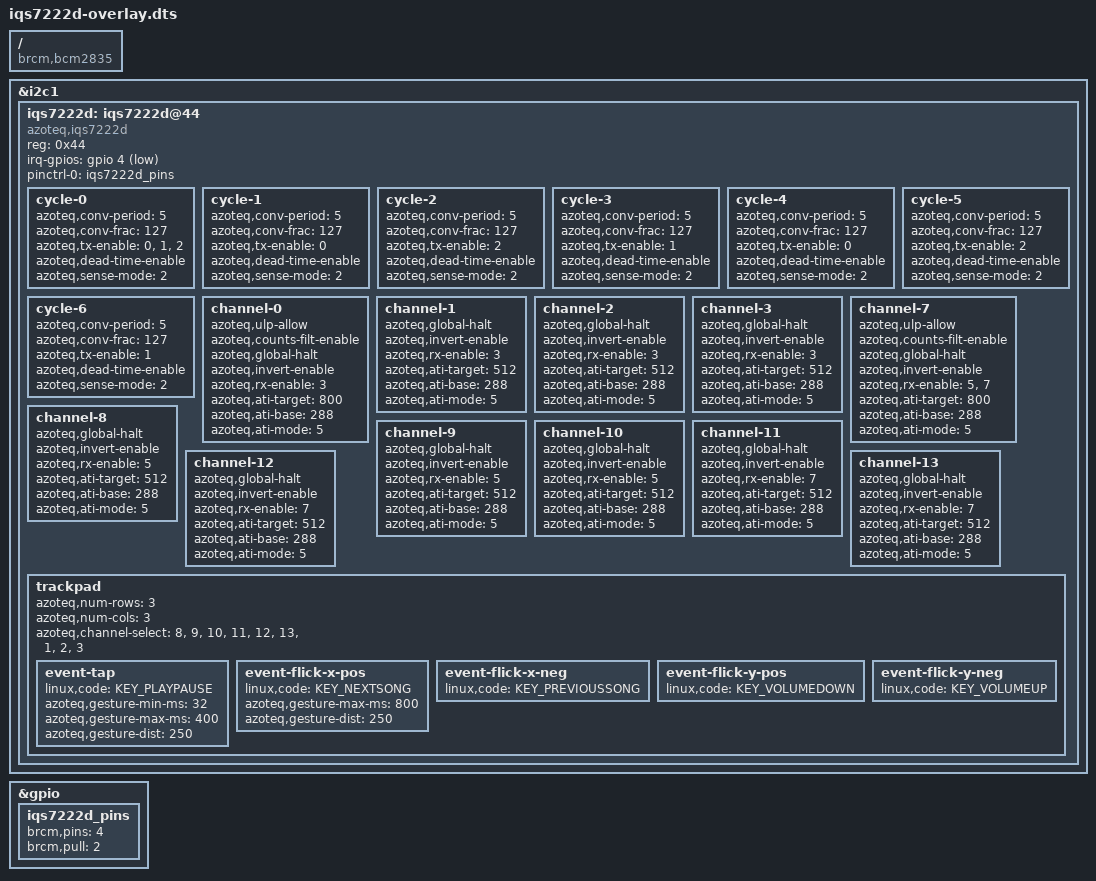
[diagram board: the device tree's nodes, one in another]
// SPDX-License-Identifier: GPL-2.0-or-later
// Definitions for Azoteq AZU045A01 + IQS7222D capacitive touch controller
/dts-v1/;
/plugin/;
#include <dt-bindings/gpio/gpio.h>
#include <dt-bindings/input/input.h>

/ {
	compatible = "brcm,bcm2835";

	fragment@0 {
		target = <&i2c1>;
		__overlay__ {
			#address-cells = <1>;
			#size-cells = <0>;
			status = "okay";

			iqs7222d: iqs7222d@44 {
				compatible = "azoteq,iqs7222d";
				reg = <0x44>;
				irq-gpios = <&gpio 4 GPIO_ACTIVE_LOW>;
				pinctrl-names = "default";
				pinctrl-0 = <&iqs7222d_pins>;

				cycle-0 {
					azoteq,conv-period = <5>;
					azoteq,conv-frac = <127>;
					azoteq,tx-enable = <0>, <1>, <2>;
					azoteq,dead-time-enable;
					azoteq,sense-mode = <2>;
				};

				cycle-1 {
					azoteq,conv-period = <5>;
					azoteq,conv-frac = <127>;
					azoteq,tx-enable = <0>;
					azoteq,dead-time-enable;
					azoteq,sense-mode = <2>;
				};

				cycle-2 {
					azoteq,conv-period = <5>;
					azoteq,conv-frac = <127>;
					azoteq,tx-enable = <2>;
					azoteq,dead-time-enable;
					azoteq,sense-mode = <2>;
				};

				cycle-3 {
					azoteq,conv-period = <5>;
					azoteq,conv-frac = <127>;
					azoteq,tx-enable = <1>;
					azoteq,dead-time-enable;
					azoteq,sense-mode = <2>;
				};

				cycle-4 {
					azoteq,conv-period = <5>;
					azoteq,conv-frac = <127>;
					azoteq,tx-enable = <0>;
					azoteq,dead-time-enable;
					azoteq,sense-mode = <2>;
				};

				cycle-5 {
					azoteq,conv-period = <5>;
					azoteq,conv-frac = <127>;
					azoteq,tx-enable = <2>;
					azoteq,dead-time-enable;
					azoteq,sense-mode = <2>;
				};

				cycle-6 {
					azoteq,conv-period = <5>;
					azoteq,conv-frac = <127>;
					azoteq,tx-enable = <1>;
					azoteq,dead-time-enable;
					azoteq,sense-mode = <2>;
				};

				channel-0 {
					azoteq,ulp-allow;
					azoteq,counts-filt-enable;
					azoteq,global-halt;
					azoteq,invert-enable;
					azoteq,rx-enable = <3>;
					azoteq,ati-target = <800>;
					azoteq,ati-base = <288>;
					azoteq,ati-mode = <5>;
				};

				channel-1 {
					azoteq,global-halt;
					azoteq,invert-enable;
					azoteq,rx-enable = <3>;
					azoteq,ati-target = <512>;
					azoteq,ati-base = <288>;
					azoteq,ati-mode = <5>;
				};

				channel-2 {
					azoteq,global-halt;
					azoteq,invert-enable;
					azoteq,rx-enable = <3>;
					azoteq,ati-target = <512>;
					azoteq,ati-base = <288>;
					azoteq,ati-mode = <5>;
				};

				channel-3 {
					azoteq,global-halt;
					azoteq,invert-enable;
					azoteq,rx-enable = <3>;
					azoteq,ati-target = <512>;
					azoteq,ati-base = <288>;
					azoteq,ati-mode = <5>;
				};

				channel-7 {
					azoteq,ulp-allow;
					azoteq,counts-filt-enable;
					azoteq,global-halt;
					azoteq,invert-enable;
					azoteq,rx-enable = <5>, <7>;
					azoteq,ati-target = <800>;
					azoteq,ati-base = <288>;
					azoteq,ati-mode = <5>;
				};

				channel-8 {
					azoteq,global-halt;
					azoteq,invert-enable;
					azoteq,rx-enable = <5>;
					azoteq,ati-target = <512>;
					azoteq,ati-base = <288>;
					azoteq,ati-mode = <5>;
				};

				channel-9 {
					azoteq,global-halt;
					azoteq,invert-enable;
					azoteq,rx-enable = <5>;
					azoteq,ati-target = <512>;
					azoteq,ati-base = <288>;
					azoteq,ati-mode = <5>;
				};

				channel-10 {
					azoteq,global-halt;
					azoteq,invert-enable;
					azoteq,rx-enable = <5>;
					azoteq,ati-target = <512>;
					azoteq,ati-base = <288>;
					azoteq,ati-mode = <5>;
				};

				channel-11 {
					azoteq,global-halt;
					azoteq,invert-enable;
					azoteq,rx-enable = <7>;
					azoteq,ati-target = <512>;
					azoteq,ati-base = <288>;
					azoteq,ati-mode = <5>;
				};

				channel-12 {
					azoteq,global-halt;
					azoteq,invert-enable;
					azoteq,rx-enable = <7>;
					azoteq,ati-target = <512>;
					azoteq,ati-base = <288>;
					azoteq,ati-mode = <5>;
				};

				channel-13 {
					azoteq,global-halt;
					azoteq,invert-enable;
					azoteq,rx-enable = <7>;
					azoteq,ati-target = <512>;
					azoteq,ati-base = <288>;
					azoteq,ati-mode = <5>;
				};

				trackpad {
					azoteq,num-rows = <3>;
					azoteq,num-cols = <3>;
					azoteq,channel-select = <8>, <9>, <10>,
								<11>, <12>, <13>,
								<1>, <2>, <3>;

					event-tap {
						linux,code = <KEY_PLAYPAUSE>;
						azoteq,gesture-min-ms = <32>;
						azoteq,gesture-max-ms = <400>;
						azoteq,gesture-dist = <250>;
					};

					event-flick-x-pos {
						linux,code = <KEY_NEXTSONG>;
						azoteq,gesture-max-ms = <800>;
						azoteq,gesture-dist = <250>;
					};

					event-flick-x-neg {
						linux,code = <KEY_PREVIOUSSONG>;
					};

					event-flick-y-pos {
						linux,code = <KEY_VOLUMEDOWN>;
					};

					event-flick-y-neg {
						linux,code = <KEY_VOLUMEUP>;
					};
				};
			};
		};
	};

	fragment@1 {
		target = <&iqs7222d>;
		iqs7222d_reset: __dormant__ {
			reset-gpios = <&gpio 255 (GPIO_ACTIVE_LOW |
						  GPIO_PUSH_PULL)>;
		};
	};

	fragment@2 {
		target = <&gpio>;
		__overlay__ {
			iqs7222d_pins: iqs7222d_pins {
				brcm,pins = <4>;
				brcm,pull = <2>;
			};
		};
	};

	__overrides__ {
		interrupt = <&iqs7222d>,"irq-gpios:4",
			    <&iqs7222d_pins>,"brcm,pins:0";
		reset = <0>,"+1", <&iqs7222d_reset>,"reset-gpios:4";
		addr = <&iqs7222d>,"reg:0";
	};
};
